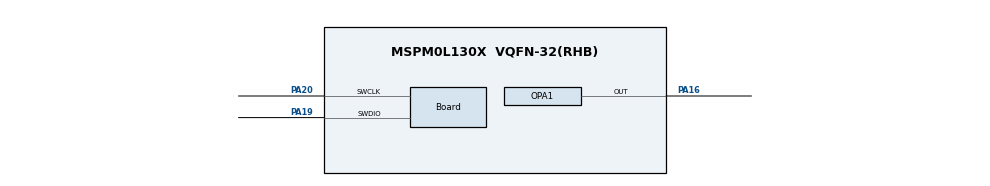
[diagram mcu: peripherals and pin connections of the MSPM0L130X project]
/**
 * @cliArgs --device "MSPM0L130X" --package "VQFN-32(RHB)" --part "Default" --product "mspm0_sdk@1.20.01.06"
 * @versions {"tool":"1.18.1+3343"}
 */

/**
 * Import the modules used in this configuration.
 */
const ADC12  = scripting.addModule("/ti/driverlib/ADC12", {}, false);
const ADC121 = ADC12.addInstance();
const Board  = scripting.addModule("/ti/driverlib/Board");
const COMP   = scripting.addModule("/ti/driverlib/COMP", {}, false);
const COMP1  = COMP.addInstance();
const GPAMP  = scripting.addModule("/ti/driverlib/GPAMP", {}, false);
const GPAMP1 = GPAMP.addInstance();
const GPIO   = scripting.addModule("/ti/driverlib/GPIO", {}, false);
const GPIO1  = GPIO.addInstance();
const GPIO2  = GPIO.addInstance();
const OPA    = scripting.addModule("/ti/driverlib/OPA", {}, false);
const OPA1   = OPA.addInstance();
const OPA2   = OPA.addInstance();
const SYSCTL = scripting.addModule("/ti/driverlib/SYSCTL");
const TIMER  = scripting.addModule("/ti/driverlib/TIMER", {}, false);
const TIMER1 = TIMER.addInstance();

/**
 * Write custom configuration values to the imported modules.
 */
ADC121.$name                 = "ADC12_0";
ADC121.sampClkSrc            = "DL_ADC12_CLOCK_ULPCLK";
ADC121.sampClkDiv            = "DL_ADC12_CLOCK_DIVIDE_8";
ADC121.repeatMode            = true;
ADC121.sampleTime0           = "0.1ms";
ADC121.adcMem1chansel        = "DL_ADC12_INPUT_CHAN_12";
ADC121.enabledInterrupts     = ["DL_ADC12_INTERRUPT_MEM0_RESULT_LOADED","DL_ADC12_INTERRUPT_MEM1_RESULT_LOADED"];
ADC121.adcMem1bcsen          = true;
ADC121.adcMem1stime          = "DL_ADC12_SAMPLE_TIMER_SOURCE_SCOMP1";
ADC121.adcMem1avgen          = true;
ADC121.samplingOperationMode = "sequence";
ADC121.enableHWAverage       = false;
ADC121.endAdd                = 1;
ADC121.sampleTime1           = "0.1 ms";
ADC121.adcPin0Config.$name   = "ti_driverlib_gpio_GPIOPinGeneric1";

Board.InitPriority8               = "/ti/driverlib/VREF";
Board.peripheral.$assign          = "DEBUGSS";
Board.peripheral.swclkPin.$assign = "PA20";
Board.peripheral.swdioPin.$assign = "PA19";

COMP1.$name              = "COMP_0";
COMP1.hysteresis         = "DL_COMP_HYSTERESIS_20";
COMP1.vSource            = "DL_COMP_REF_SOURCE_VDDA_DAC";
COMP1.terminalSelect     = "DL_COMP_REF_TERMINAL_SELECT_NEG";
COMP1.controlSelect      = "DL_COMP_DAC_CONTROL_SW";
COMP1.setDACCode0        = 0x4D;
COMP1.peripheral.$assign = "COMP0";

GPAMP1.$name                = "GPAMP_0";
GPAMP1.cfgPSELChannel       = "IN_POS";
GPAMP1.cfgOutputPin         = "ENABLED";
GPAMP1.profile              = "CONFIG_PROFILE_3";
GPAMP1.InPosPinConfig.$name = "ti_driverlib_gpio_GPIOPinGeneric2";
GPAMP1.OutPinConfig.$name   = "ti_driverlib_gpio_GPIOPinGeneric3";

GPIO1.$name                          = "A";
GPIO1.associatedPins[0].assignedPort = "PORTA";
GPIO1.associatedPins[0].$name        = "PIN_8";
GPIO1.associatedPins[0].assignedPin  = "8";

GPIO2.$name                          = "PA";
GPIO2.associatedPins[0].$name        = "PIN_9";
GPIO2.associatedPins[0].assignedPort = "PORTA";
GPIO2.associatedPins[0].assignedPin  = "9";

OPA1.cfg0OutputPin                    = "ENABLED";
OPA1.cfg0NSELChannel                  = "RTOP";
OPA1.advBW                            = "HIGH";
OPA1.cfg0PSELChannel                  = "DAC8_OUT";
OPA1.$name                            = "OPA_1";
OPA1.profile                          = "CONFIG_PROFILE_3";
OPA1.peripheral.$assign               = "OPA1";
OPA1.peripheral.OutPin.$assign        = "PA16";
OPA1.OutPinConfig.$name               = "ti_driverlib_gpio_GPIOPinGeneric0";
OPA1.OutPinConfig.direction           = scripting.forceWrite("OUTPUT");
OPA1.OutPinConfig.hideOutputInversion = scripting.forceWrite(false);

OPA2.$name                 = "OPA_0";
OPA2.cfg0PSELChannel       = "IN0_POS";
OPA2.cfg0Gain              = "N1_P2";
OPA2.cfg0NSELChannel       = "RTAP";
OPA2.cfg0MSELChannel       = "GND";
OPA2.cfg0Chop              = "STANDARD";
OPA2.In0PosPinConfig.$name = "ti_driverlib_gpio_GPIOPinGeneric4";

SYSCTL.clockTreeEn = true;

TIMER1.$name            = "TIMER_0";
TIMER1.timerClkPrescale = 256;
TIMER1.timerMode        = "PERIODIC";
TIMER1.interrupts       = ["ZERO"];
TIMER1.timerPeriod      = "0.1 ms";

/**
 * Pinmux solution for unlocked pins/peripherals. This ensures that minor changes to the automatic solver in a future
 * version of the tool will not impact the pinmux you originally saw.  These lines can be completely deleted in order to
 * re-solve from scratch.
 */
ADC121.peripheral.$suggestSolution           = "ADC0";
ADC121.peripheral.adcPin0.$suggestSolution   = "PA27";
GPAMP1.peripheral.$suggestSolution           = "GPAMP";
GPAMP1.peripheral.InPosPin.$suggestSolution  = "PA26";
GPAMP1.peripheral.OutPin.$suggestSolution    = "PA22";
GPIO1.associatedPins[0].pin.$suggestSolution = "PA8";
GPIO2.associatedPins[0].pin.$suggestSolution = "PA9";
OPA2.peripheral.$suggestSolution             = "OPA0";
OPA2.peripheral.In0PosPin.$suggestSolution   = "PA25";
TIMER1.peripheral.$suggestSolution           = "TIMG0";
